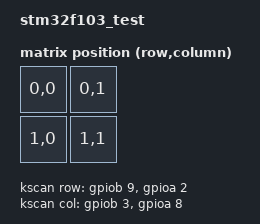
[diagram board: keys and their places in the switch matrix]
// This file was generated from a template. Edit it to match your keyboard.
// See https://docs.zephyrproject.org/3.5.0/hardware/porting/board_porting.html
// and https://zmk.dev/docs/development/hardware-integration/new-shield for more
// instructions.

/dts-v1/;
#include <dt-bindings/zmk/matrix_transform.h>

#include <st/f1/stm32f103X8.dtsi>
#include <st/f1/stm32f103r(8-b)tx-pinctrl.dtsi>

#include "stm32f103_test-layouts.dtsi"

/ {
    model = "stm32f103_test";
	compatible = "st,stm32f103c8";


    chosen {
        zmk,physical-layout = &default_layout;
    };

    kscan: kscan {
        // If the hardware does not use a switch matrix, change this to the
        // appropriate driver and update the properties below to match.
        // See https://zmk.dev/docs/config/kscan for supported key scan drivers.
        compatible = "zmk,kscan-gpio-matrix";
        // Set this to "col2row" or "row2col" to match the hardware. If using
        // "row2col", change the col-gpios to (GPIO_ACTIVE_HIGH | GPIO_PULL_DOWN)
        // and the row-gpios to GPIO_ACTIVE_HIGH.
        diode-direction = "col2row";
        wakeup-source;

        // Replace these comments with the GPIO pins in the matrix.
        // See https://zmk.dev/docs/development/hardware-integration/new-shield#shield-overlays
        col-gpios
            = <&gpiob 3 GPIO_ACTIVE_HIGH>
            , <&gpioa 8 GPIO_ACTIVE_HIGH>
            ;

        row-gpios
            = <&gpiob 9 (GPIO_ACTIVE_HIGH | GPIO_PULL_DOWN)>
            , <&gpioa 2 (GPIO_ACTIVE_HIGH | GPIO_PULL_DOWN)>
            ;
    };

    default_transform: default_transform {
        // See https://zmk.dev/docs/development/hardware-integration/new-shield#matrix-transform
        // for how to configure this
        compatible = "zmk,matrix-transform";
        columns = <2>;
        rows = <2>;

        map = <
            RC(0, 0) RC(0, 1)
            RC(1, 0) RC(1, 1)
        >;
    };

    

};

&clk_hse {
    clock-frequency = <DT_FREQ_M(16)>;
    status = "okay";
};

&pll {
   xtpre;
   mul = <9>;
   clocks = <&clk_hse>;
   status = "okay";
};

&rcc {
    clocks = <&pll>;
    clock-frequency = <DT_FREQ_M(72)>;
    ahb-prescaler = <1>;
    apb1-prescaler = <2>;
    apb2-prescaler = <1>;
    /* usbpre not set: USB clock = 72 / 1.5: 48MHz */
};

&usart1 {
    pinctrl-0 = <&usart1_tx_pa9 &usart1_rx_pa10>;
    current-speed = <115200>;
    pinctrl-names = "default";
    status = "okay";
};

&usart2 {
    pinctrl-0 = <&usart2_tx_pa2 &usart2_rx_pa3>;
    current-speed = <115200>;
    pinctrl-names = "default";
    status = "okay";
};

&usart3 {
    pinctrl-0 = <&usart3_tx_pb10 &usart3_rx_pb11>;
    current-speed = <115200>;
    pinctrl-names = "default";
    status = "okay";
};

&i2c1 {
    pinctrl-0 = < &i2c1_scl_pb6 &i2c1_sda_pb7 >;
    status = "okay";
    pinctrl-names = "default";
    clock-frequency = <I2C_BITRATE_FAST>;
};

&i2c2 {
    pinctrl-0 = < &i2c2_scl_pb10 &i2c2_sda_pb11 >;
    pinctrl-names = "default";
    status = "okay";
    clock-frequency = <I2C_BITRATE_FAST>;
};

&spi1 {
    pinctrl-0 = <&spi1_nss_master_pa4 &spi1_sck_master_pa5
             &spi1_miso_master_pa6 &spi1_mosi_master_pa7>;
    pinctrl-names = "default";
    status = "okay";
};

&spi2 {
    pinctrl-0 = <&spi2_nss_master_pb12 &spi2_sck_master_pb13
             &spi2_miso_master_pb14 &spi2_mosi_master_pb15>;
    pinctrl-names = "default";
    status = "okay";
};

&timers1 {
    status = "okay";

    pwm1: pwm {
        status = "okay";
        pinctrl-0 = <&tim1_ch1_pwm_out_pa8>;
        pinctrl-names = "default";
    };
};

zephyr_udc0: &usb {
    pinctrl-0 = <&usb_dm_pa11 &usb_dp_pa12>;
    pinctrl-names = "default";
    status = "okay";
};

&adc1 {
    pinctrl-0 = <&adc1_in0_pa0>;
    pinctrl-names = "default";
    status = "okay";
};
